# AT91SAM9M11 register map
Vendor: Atmel; File version: 20130207
CPU: 
Registers are 32-bit, read-write, no defined reset value unless marked. A register's access mark holds for its fields unless they carry their own. Offsets are from the block's base; [hi:lo] are bit positions; {n}, {i} and the like mark numbered series.

## SHA — Secure Hash Algorithm
Base 0xFFFC8000; register names take the prefix SHA_
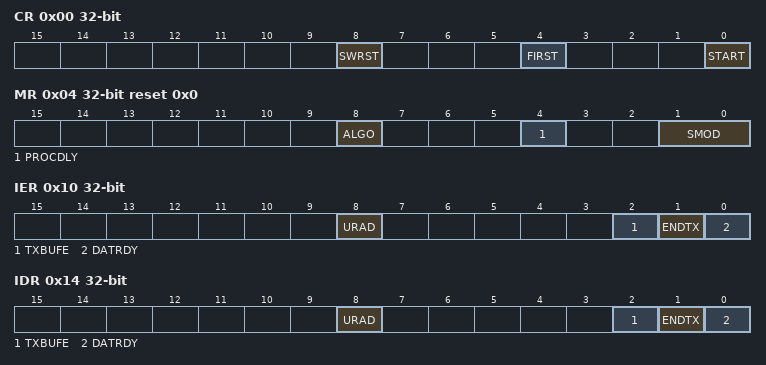
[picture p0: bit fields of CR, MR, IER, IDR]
0x00 CR wo — Control Register
  [8] SWRST — Software Reset
  [4] FIRST — First Block of a Message
  [0] START — Start Processing
0x04 MR reset 0x0 — Mode Register
  [8] ALGO — SHA Algorithm
  [4] PROCDLY — Processing Delay
  [1:0] SMOD — Start Mode
0x10 IER wo — Interrupt Enable Register
  [8] URAD — Unspecified Register Access Detection Interrupt Enable
  [2] TXBUFE — Transmit Buffer Empty Interrupt Enable
  [1] ENDTX — End of Transmit Buffer Interrupt Enable
  [0] DATRDY — Data Ready Interrupt Enable
0x14 IDR wo — Interrupt Disable Register
  [8] URAD — Unspecified Register Access Detection Interrupt Disable
  [2] TXBUFE — Transmit Buffer Empty Interrupt Disable
  [1] ENDTX — End of Transmit Buffer Interrupt Disable
  [0] DATRDY — Data Ready Interrupt Disable
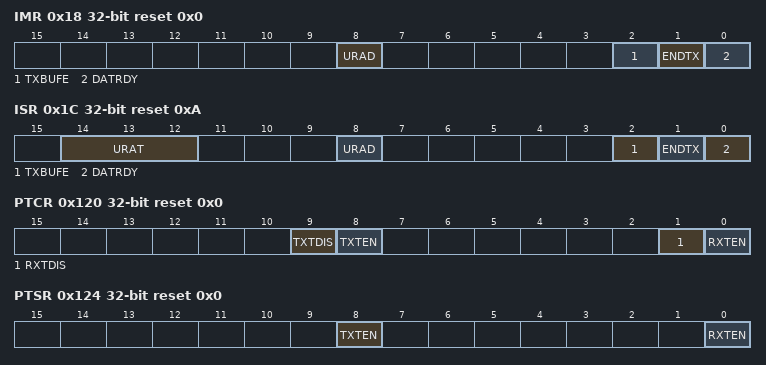
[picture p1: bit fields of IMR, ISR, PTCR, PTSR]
0x18 IMR ro reset 0x0 — Interrupt Mask Register
  [8] URAD — Unspecified Register Access Detection Interrupt Mask
  [2] TXBUFE — Transmit Buffer Empty Interrupt Mask
  [1] ENDTX — End of Transmit Buffer Interrupt Mask
  [0] DATRDY — Data Ready Interrupt Mask
0x1C ISR ro reset 0xA — Interrupt Status Register
  [14:12] URAT — Unspecified Register Access Type
  [8] URAD — Unspecified Register Access Detection Status
  [2] TXBUFE — TX Buffer Empty
  [1] ENDTX — End of TX Buffer
  [0] DATRDY — Data Ready
{0x40+4i} IDATAxR[{i}] wo (i=0..15) — Input Data Register
  [31:0] IDATAx — Input Data x
{0x80+4i} ODATAxR[{i}] ro (i=0..7) — Output Data Register
  [31:0] ODATAx — Output Data x
0x108 TPR reset 0x0 — Transmit Pointer Register
  [31:0] TXPTR — Transmit Counter Register
0x10C TCR reset 0x0 — Transmit Counter Register
  [15:0] TXCTR
0x118 TNPR reset 0x0 — Transmit Next Pointer Register
  [31:0] TXNPTR — Transmit Next Pointer
0x11C TNCR reset 0x0 — Transmit Next Counter Register
  [15:0] TXNCTR — Transmit Counter Next
0x120 PTCR wo reset 0x0 — Transfer Control Register
  [9] TXTDIS — Transmitter Transfer Disable
  [8] TXTEN — Transmitter Transfer Enable
  [1] RXTDIS — Receiver Transfer Disable
  [0] RXTEN — Receiver Transfer Enable
0x124 PTSR ro reset 0x0 — Transfer Status Register
  [8] TXTEN — Transmitter Transfer Enable
  [0] RXTEN — Receiver Transfer Enable

## TRNG — True Random Number Generator
Base 0xFFFCC000; register names take the prefix TRNG_
0x00 CR wo — Control Register
  [0] ENABLE — Enables the TRNG to provide random values
0x10 IER wo — Interrupt Enable Register
  [0] DATRDY — Data Ready Interrupt Enable
0x14 IDR wo — Interrupt Disable Register
  [0] DATRDY — Data Ready Interrupt Disable
0x18 IMR ro reset 0x0 — Interrupt Mask Register
  [0] DATRDY — Data Ready Interrupt Mask
0x1C ISR ro reset 0x0 — Interrupt Status Register
  [0] DATRDY — Data Ready
0x50 ODATA ro reset 0x0 — Output Data Register
  [31:0] ODATA — Output Data

## DDRSDRC1 — DDR_SDR SDRAM Controller 1
Base 0xFFFFE400; register names take the prefix DDRSDRC1_
0x00 MR reset 0x0 — DDRSDRC Mode Register
  [2:0] MODE — DDRSDRC Command Mode
0x04 RTR reset 0x0 — DDRSDRC Refresh Timer Register
  [11:0] COUNT — DDRSDRC Refresh Timer Count
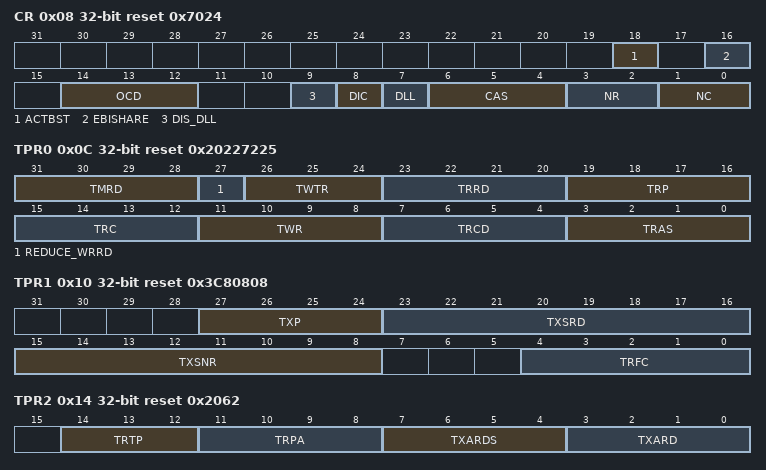
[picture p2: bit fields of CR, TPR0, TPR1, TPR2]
0x08 CR reset 0x7024 — DDRSDRC Configuration Register
  [18] ACTBST — ACTIVE Bank X to Burst Stop Read Access Bank Y
  [16] EBISHARE — External Bus Interface is Shared
  [14:12] OCD — Off-chip Driver
  [9] DIS_DLL — Disable DLL
  [8] DIC — Output Driver Impedance Control
  [7] DLL — Reset DLL
  [6:4] CAS — CAS Latency
  [3:2] NR — Number of Row Bits
  [1:0] NC — Number of Column Bits
0x0C TPR0 reset 0x20227225 — DDRSDRC Timing Parameter 0 Register
  [31:28] TMRD — Load Mode Register Command to Active or Refresh Command
  [27] REDUCE_WRRD — Reduce Write to Read Delay
  [26:24] TWTR — Internal Write to Read Delay
  [23:20] TRRD — Active bankA to Active bankB
  [19:16] TRP — Row Precharge Delay
  [15:12] TRC — Row Cycle Delay
  [11:8] TWR — Write Recovery Delay
  [7:4] TRCD — Row to Column Delay
  [3:0] TRAS — Active to Precharge Delay
0x10 TPR1 reset 0x3C80808 — DDRSDRC Timing Parameter 1 Register
  [27:24] TXP — Exit Power-down Delay to First Command
  [23:16] TXSRD — ExiT Self Refresh Delay to Read Command
  [15:8] TXSNR — Exit Self Refresh Delay to Non-read Command
  [4:0] TRFC — Row Cycle Delay
0x14 TPR2 reset 0x2062 — DDRSDRC Timing Parameter 2 Register
  [14:12] TRTP — Read to Precharge
  [11:8] TRPA — Row Precharge All Delay
  [7:4] TXARDS — Exit Active Power Down Delay to Read Command in Mode "Slow Exit".
  [3:0] TXARD — Exit Active Power Down Delay to Read Command in Mode "Fast Exit".
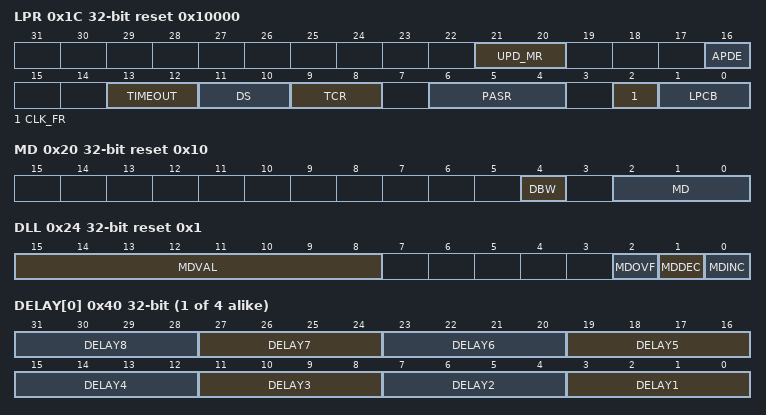
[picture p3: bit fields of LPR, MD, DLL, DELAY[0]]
0x1C LPR reset 0x10000 — DDRSDRC Low-power Register
  [21:20] UPD_MR — Update Load Mode Register and Extended Mode Register
  [16] APDE — Active Power Down Exit Time
  [13:12] TIMEOUT — Low Power Mode
  [11:10] DS — Drive Strength
  [9:8] TCR — Temperature Compensated Self Refresh
  [6:4] PASR — Partial Array Self Refresh
  [2] CLK_FR — Clock Frozen Command Bit
  [1:0] LPCB — Low-power Command Bit
0x20 MD reset 0x10 — DDRSDRC Memory Device Register
  [4] DBW — Data Bus Width
  [2:0] MD — Memory Device
0x24 DLL ro reset 0x1 — DDRSDRC DLL Information Register
  [15:8] MDVAL — DLL Master Delay Value
  [2] MDOVF — DLL Master Delay Overflow Flag
  [1] MDDEC — DLL Master Delay Decrement
  [0] MDINC — DLL Master Delay Increment
0x2C HS reset 0x0 — DDRSDRC High Speed Register
  [2] DIS_ANTICIP_READ — Anticip Read Access
{0x40+4i} DELAY[{i}] (i=0..3) — DDRSDRC Delay I/O Register
  [4n-1:4n-4] DELAY{n} (n=1..8) — Delay1..Delay8
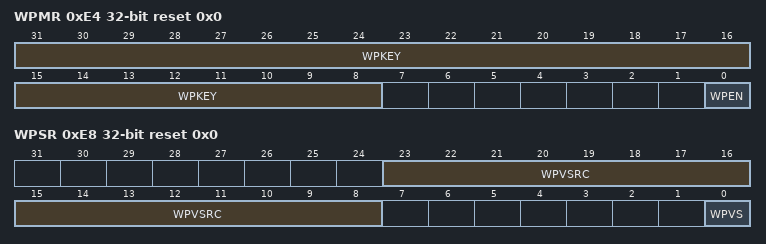
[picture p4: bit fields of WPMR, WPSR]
0xE4 WPMR reset 0x0 — DDRSDRC Write Protect Mode Register
  [31:8] WPKEY — Write Protect KEY
  [0] WPEN — Write Protect Enable
0xE8 WPSR ro reset 0x0 — DDRSDRC Write Protect Status Register
  [23:8] WPVSRC — Write Protect Violation Source
  [0] WPVS — Write Protect Violation Status

## DDRSDRC0 — DDR_SDR SDRAM Controller 0
Base 0xFFFFE600; register names take the prefix DDRSDRC0_
Registers as DDRSDRC1.
